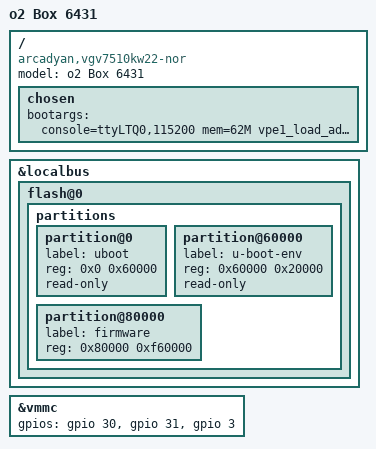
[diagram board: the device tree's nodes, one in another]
/dts-v1/;

#include "vr9_arcadyan_vgv7510kw22.dtsi"

/ {
	compatible = "arcadyan,vgv7510kw22-nor", "arcadyan,vgv7510kw22", "lantiq,xway", "lantiq,vr9";
	model = "o2 Box 6431";
	
	chosen {
                bootargs = "console=ttyLTQ0,115200 mem=62M vpe1_load_addr=0x83e00000 vpe1_mem=2M maxvpes=1 maxtcs=1 nosmp";
		};
};

&localbus {
	flash@0 {
		partitions {
			partition@0 {
				label = "uboot";
				reg = <0x0 0x60000>; /* 384 KiB */
				read-only;
			};

			partition@60000 {
				label = "u-boot-env";
				reg = <0x60000 0x20000>; /* 128 KiB */
				read-only;
			};

			partition@80000 {
				label = "firmware";
				reg = <0x80000 0xf60000>; /* 15744 KiB */
			};
		};
	};
};

&vmmc {
		status = "okay";
        gpios = <&gpio 30 GPIO_ACTIVE_HIGH  //fxs relay
				&gpio 31 GPIO_ACTIVE_HIGH  //still unknown
                &gpio 3  GPIO_ACTIVE_HIGH>; //reset_slic?
};
